# CKGEN_CM_CORE register map
Vendor: Texas Instruments
Peripheral module from a debugger description file (folder omap5430_ES2_PUBLIC).
Registers are 32-bit, access per field, reset 0x0 unless marked. A register's access mark holds for its fields unless they carry their own. Offsets are as the file gives them; lines under a group give offsets from that group; [hi:lo] are bit positions; {n}, {i} and the like mark numbered series; 'fields as' and 'values as' point back to an identical list; <NAME> marks a mode.

## CKGEN_CM_CORE
0x04 CM_CLKSEL_USB_60MHZ reset 0x1 — Selects the configuration of the divider generating 60MHz clock for USB from the DPLL_USB o/p.
  [0] CLKSEL rw — Select the configuration of the divider
    0=SEL_DIV_1 (Set the divider in bypass mode to support bypass clock from DPLL_USB to pass through without division.); 1=SEL_DIV_8 (Set the divider to divide the DPLL o/p (480MHz typical) by 8 to generate 60MHz clock, to be used for both OPP_NOM and OPP_LOW.)
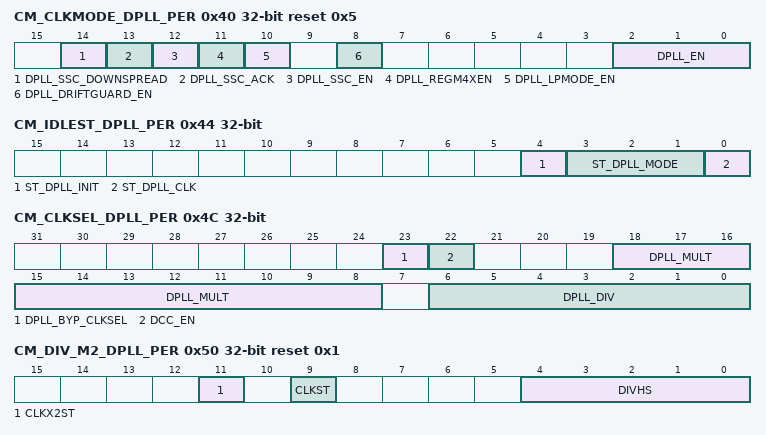
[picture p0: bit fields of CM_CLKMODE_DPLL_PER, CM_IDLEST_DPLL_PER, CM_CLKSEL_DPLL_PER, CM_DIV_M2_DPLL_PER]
0x40 CM_CLKMODE_DPLL_PER reset 0x5 — This register allows controlling the DPLL modes.
  [14] DPLL_SSC_DOWNSPREAD rw — Control if only low frequency spread is required
    0=FULL_SPREAD (When SSC is enabled, clock frequency is spread on both sides of the programmed frequency); 1=LOW_SPREAD (When SSC is enabled, clock frequency is spread only on the lower side of the programmed frequency)
  [13] DPLL_SSC_ACK ro — Acknowledgement from the DPLL regarding start and stop of Spread Spectrum Clocking feature
    0=Disabled (SSC has been turned off on PLL o/ps); 1=Enabled (SSC has been turned on on PLL o/ps)
  [12] DPLL_SSC_EN rw — Enable or disable Spread Spectrum Clocking
    0=Disabled (SSC disabled); 1=Enabled (SSC enabled)
  [11] DPLL_REGM4XEN ro — Enable the REGM4XEN mode of the DPLL.
    0=DISABLED (REGM4XEN mode of the DPLL is disabled)
  [10] DPLL_LPMODE_EN rw — Set the DPLL in Low Power mode. Check the DPLL documentation to see when this can be enabled.
    0=DISABLED (Low power mode of the DPLL is disabled); 1=ENABLED (Low power mode of the DPLL is enabled)
  [8] DPLL_DRIFTGUARD_EN rw — This bit allows to enable or disable the automatic recalibration feature of the DPLL. The DPLL will automatically start a recalibration process upon assertion of the DPLL's RECAL flag if this bit is set.
    0=Diasbled (DRIFTGUARD feature is disabled); 1=Enabled (DRIFTGUARD feature is enabled)
  [2:0] DPLL_EN rw — DPLL control
    5=DPLL_LP_BYP_MODE (Put the DPLL in Idle Bypass Low Power mode.); 6=DPLL_FR_BYP_MODE (Put the DPLL in Idle Bypass Fast Relock mode.); 7=DPLL_LOCK_MODE (Enables the DPLL in Lock mode)
0x44 CM_IDLEST_DPLL_PER ro — This register allows monitoring DPLL activity. This register is read only and automatically updated. [warm reset insensitive]
  [4] ST_DPLL_INIT — DPLL init status (for debug purpose).
    1=DPLL_INIT (DPLL has been init); 0=DPLL_NOTINIT (DPLL is not init)
  [3:1] ST_DPLL_MODE — DPLL mode status (for debug purpose)
    0=Transient state. From reset to any LP (low power) idle state or from any power state to any power state (Power states are Low Power Stop mode, Fast Relock Stop mode, Idle Bypass Low Power mode and Idle Bypass Fast Relock mode).; 1=LP_STOP (The DPLL is in Low Power Stop mode); 2=FR_STOP (The DPLL is in Fast Relock Stop mode); 5=LP_BYP (The DPLL is in Idle Bypass Low Power mode); 6=FR_BYP (The DPLL is in Idle Bypass Fast Relock mode)
  [0] ST_DPLL_CLK — DPLL lock status
    1=DPLL_LOCKED (DPLL is LOCKED); 0=DPLL_UNLOCKED (DPLL is either in bypass mode or in stop mode.)
0x48 CM_AUTOIDLE_DPLL_PER — This register provides automatic control over the DPLL activity.
  [2:0] AUTO_DPLL_MODE rw — DPLL automatic control;
    0=AUTO_CTL_DISABLE (DPLL auto control disabled); 1=AUTO_LP_STOP (The DPLL is automatically put in Low Power Stop mode when its DPLL generated clocks are not required anymore. It is also restarted automatically.); 2=AUTO_FR_STOP (The DPLL is automatically put in Fast Relock Stop mode when its DPLL generated clocks are not required anymore. It is also restarted automatically.); 5=AUTO_LP_BYP (The DPLL is automatically put in Idle Bypass Low Power mode when its DPLL generated clocks are not required anymore. It is also restarted automatically.); 6=AUTO_FR_BYP (The DPLL is automatically put in Idle Bypass Fast Relock mode when its DPLL generated clocks are not required anymore. It is also restarted automatically.)
0x4C CM_CLKSEL_DPLL_PER — This register provides controls over the DPLL.
  [23] DPLL_BYP_CLKSEL rw — Allows control of the BYPASS clock of the PLL and the associated HSDIVIDER. Same as ULOWCLKEN on DPLL. In DPLL Locked mode, 0 - No impact 1 - No impact In DPLL Bypass mode, 0 - CLKINP is selected as the BYPASS clock for CLKOUT/CLKOUTX2, 1 - CLKINPULOW is selected as the BYPASS clock for CLKOUT/CLKOUTX2
  [22] DCC_EN ro — Duty-cycle corrector for high frequency clock Read 0: Duty-cycle corrector is disabled
  [18:8] DPLL_MULT rw — DPLL multiplier factor (2 to 2047). Equal to input M of DPLL; M=2 to 2047 = DPLL multiplies by M. [warm reset insensitive]
  [6:0] DPLL_DIV rw — DPLL divider factor (0 to 127) Equal to input N of DPLL; actual division factor is N+1. [warm reset insensitive]
0x50 CM_DIV_M2_DPLL_PER reset 0x1 — This register provides controls over the M2 divider of the DPLL.
  [11] CLKX2ST ro — DPLL CLKOUTX2 status
    0=CLK_GATED (The clock output is gated); 1=CLK_ENABLED (The clock output is enabled)
  [9] CLKST ro — DPLL CLKOUT status
    values as CLKX2ST
  [4:0] DIVHS rw — DPLL M2 post-divider factor (1 to 31).
    4=Reserved (4, to be used for both OPP_NOM and OPP_LOW)
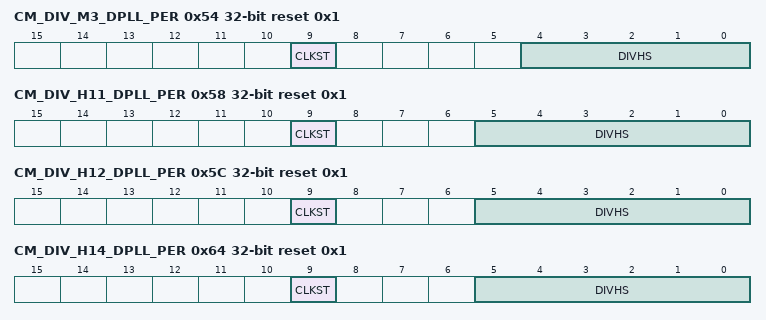
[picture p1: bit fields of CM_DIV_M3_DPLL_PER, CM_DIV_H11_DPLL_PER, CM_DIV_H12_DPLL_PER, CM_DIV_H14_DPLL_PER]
0x54 CM_DIV_M3_DPLL_PER reset 0x1 — This register provides controls over the M3 divider of the DPLL.
  [9] CLKST ro — DPLL CLKOUTHIF status
    values as CM_DIV_M2_DPLL_PER.CLKX2ST
  [4:0] DIVHS rw — DPLL M3 post-divider factor (1 to 31). The values listed for 0x3 and 0x4 are used for maximum supported frequency at each OPP. Higher dividers (max 31), thus lower frequencies, are also supported.
    3=OPP_NOM_DPLL_PER_3 (3, to be used for OPP_NOM (when DPLL_PER is locked at 768MHz)); 4=Reserved (4, to be used for OPP_LOW (when DPLL_PER is locked at 768MHz))
0x58 CM_DIV_H11_DPLL_PER reset 0x1 — This register provides controls over the CLKOUT1 o/p of the HSDIVIDER1.
  [9] CLKST ro — HSDIVIDER1 CLKOUT1 status
    values as CM_DIV_M2_DPLL_PER.CLKX2ST
  [5:0] DIVHS rw — DPLL (H11+1) post-divider factor (1 to 63).
    6=Reserved (6, to be used for both OPP_NOM and OPP_LOW (when DPLL_PER is locked at 768MHz))
0x5C CM_DIV_H12_DPLL_PER reset 0x1 — This register provides controls over the CLKOUT2 o/p of the HSDIVIDER1.
  [9] CLKST ro — HSDIVIDER1 CLKOUT2 status
    values as CM_DIV_M2_DPLL_PER.CLKX2ST
  [5:0] DIVHS rw — DPLL (H12+1) post-divider factor (1 to 63).
    4=Reserved (4, to be used for both OPP_NOM and OPP_LOW)
0x64 CM_DIV_H14_DPLL_PER reset 0x1 — This register provides controls over the CLKOUT4 o/p of the HSDIVIDER1.
  [9] CLKST ro — HSDIVIDER1 CLKOUT4 status
    values as CM_DIV_M2_DPLL_PER.CLKX2ST
  [5:0] DIVHS rw — DPLL (H14+1) post-divider factor (1 to 63).
    2=2,_to_be_used_for_OPP_NOM; 4=Reserved (4, to be used for OPP_LOW)
0x68 CM_SSC_DELTAMSTEP_DPLL_PER — Control the DeltaMStep parameter for Spread Spectrum Clocking. [warm reset insensitive]
  [19:0] DELTAMSTEP rw — DeltaMStep is split into fractional and integer part. For Triangular Spread Spectrum: [19:18] for integer part, [17:0] for fractional part For Square Wave Spread Spectrum [19:14] for integer part, [13:0] for fractional part
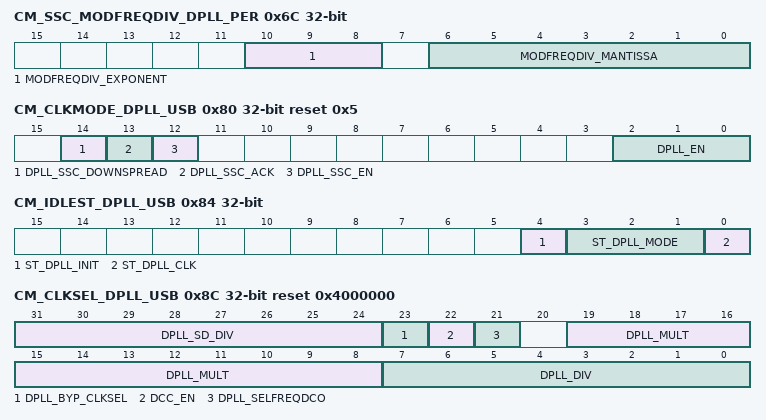
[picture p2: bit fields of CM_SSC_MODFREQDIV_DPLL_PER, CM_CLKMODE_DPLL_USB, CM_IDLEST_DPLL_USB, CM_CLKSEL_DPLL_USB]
0x6C CM_SSC_MODFREQDIV_DPLL_PER — Control the Modulation Frequency (Fm) for Spread Spectrum. [warm reset insensitive]
  [10:8] MODFREQDIV_EXPONENT rw — Set the Exponent component of MODFREQDIV factor
  [6:0] MODFREQDIV_MANTISSA rw — Set the Mantissa component of MODFREQDIV factor
0x80 CM_CLKMODE_DPLL_USB reset 0x5 — This register allows controlling the DPLL_USB modes.
  [14] DPLL_SSC_DOWNSPREAD rw — Control if only low frequency spread is required
    values as CM_CLKMODE_DPLL_PER.DPLL_SSC_DOWNSPREAD
  [13] DPLL_SSC_ACK ro — Acknowledgement from the DPLL regarding start and stop of Spread Spectrum Clocking feature
    values as CM_CLKMODE_DPLL_PER.DPLL_SSC_ACK
  [12] DPLL_SSC_EN rw — Enable or disable Spread Spectrum Clocking
    0=Disabled (SSC disabled); 1=Enabled (SSC enabled)
  [2:0] DPLL_EN rw — DPLL control. Upon Warm Reset, the PRCM DPLL control state machine updates this register to reflect DPLL Low Power Stop mode.
    1=DPLL_LP_STP_MODE (Put the DPLL in Low Power Stop mode); 5=DPLL_LP_BYP_MODE (Put the DPLL in Idle Bypass Low Power mode.); 7=DPLL_LOCK_MODE (Enables the DPLL in Lock mode)
0x84 CM_IDLEST_DPLL_USB ro — This register allows monitoring DPLL activity. This register is read only and automatically updated. [warm reset insensitive]
  [4] ST_DPLL_INIT — DPLL init status (for debug purpose).
    values as CM_IDLEST_DPLL_PER.ST_DPLL_INIT
  [3:1] ST_DPLL_MODE — DPLL mode status (for debug purpose).
    0=Transient state. From reset to any LP (low power) idle state or from any power state to any power state (Power states are Low Power Stop mode, Fast Relock Stop mode, Idle Bypass Low Power mode and Idle Bypass Fast Relock mode).; 1=LP_STOP (The DPLL is in Low Power Stop mode); 5=LP_BYP (The DPLL is in Idle Bypass Low Power mode)
  [0] ST_DPLL_CLK — DPLL lock status
    values as CM_IDLEST_DPLL_PER.ST_DPLL_CLK
0x88 CM_AUTOIDLE_DPLL_USB — This register provides automatic control over the DPLL activity.
  [2:0] AUTO_DPLL_MODE rw — DPLL automatic control;
    0=AUTO_CTL_DISABLE (DPLL auto control disabled); 1=AUTO_LP_STOP (The DPLL is automatically put in Low Power Stop mode when its DPLL generated clocks are not required anymore. It is also restarted automatically.); 5=AUTO_LP_BYP (The DPLL is automatically put in Idle Bypass Low Power mode when its DPLL generated clocks are not required anymore. It is also restarted automatically.)
0x8C CM_CLKSEL_DPLL_USB reset 0x4000000 — This register provides controls over the DPLL.
  [31:24] DPLL_SD_DIV rw — Sigma-Delta divider select (2-255). This factor must be set by software to ensure optimum jitter performance. DPLL_SD_DIV = CEILING ([DPLL_MULT/(DPLL_DIV+1)] * CLKINP / 250), where CLKINP is the input clock of the DPLL in MHz). DPLL_MULT must be set with M multiplier factor and DPLL_DIV with N divider factor, and must not be changed once DPLL is locked. For more information, see , .
  [23] DPLL_BYP_CLKSEL rw — Allows control of the BYPASS clock of the PLL and the associated HSDIVIDER. Same as ULOWCLKEN on DPLL. In DPLL Locked mode, 0 - No impact 1 - No impact In DPLL Bypass mode, 0 - CLKINP is selected as the BYPASS clock for CLKOUT 1 - CLKINPULOW is selected as the BYPASS clock for CLKOUT
  [22] DCC_EN ro — Duty-cycle corrector for high frequency clock Read 0: Duty-cycle corrector is disabled
  [21] DPLL_SELFREQDCO rw — Select DCO output according to required frequency. 0x0: DCO clock is 1500MHz SELFREQDCO input of DPLL is set to '010' 0x1: DCO clock is 1250MHz SELFREQDCO input of DPLL is set to '100''
  [19:8] DPLL_MULT rw — DPLL multiplier factor (2 to 4095). Equal to input M (multiplier) factor of DPLL; M=2 to 4095 = DPLL multiplies by M. [warm reset insensitive]
  [7:0] DPLL_DIV rw — DPLL divider factor (0 to 255) Equal to input N (divider) factor of DPLL; actual division factor is N+1 [warm reset insensitive]
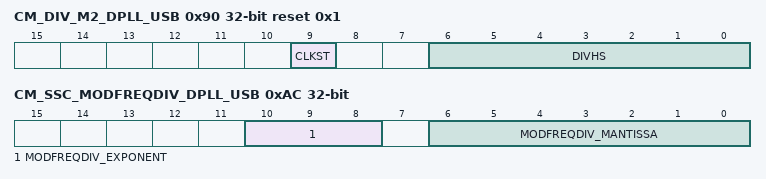
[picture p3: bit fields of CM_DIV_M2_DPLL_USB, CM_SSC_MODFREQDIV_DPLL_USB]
0x90 CM_DIV_M2_DPLL_USB reset 0x1 — This register provides controls over the M2 divider of the DPLL.
  [9] CLKST ro — DPLL CLKOUT status
    values as CM_DIV_M2_DPLL_PER.CLKX2ST
  [6:0] DIVHS rw — DPLL M2 post-divider factor (1 to 127).
    2=Reserved (2, to be used for both OPP_NOM and OPP_LOW)
0xA8 CM_SSC_DELTAMSTEP_DPLL_USB — Control the DeltaMStep parameter for Spread Spectrum Clocking. [warm reset insensitive]
  [20:0] DELTAMSTEP rw — DeltaMStep is split into fractional and integer part. For Triangular Spread Spectrum: [20:18] for integer part, [17:0] for fractional part For Square Wave Spread Spectrum [19:14] for integer part, [13:0] for fractional part
0xAC CM_SSC_MODFREQDIV_DPLL_USB — Control the Modulation Frequency (Fm) for Spread Spectrum. [warm reset insensitive]
  fields as CM_SSC_MODFREQDIV_DPLL_PER
0xB4 CM_CLKDCOLDO_DPLL_USB ro — This register provides status over CLKDCOLDO output of the DPLL.
  [9] ST_DPLL_CLKDCOLDO — DPLL CLKDCOLDO status
    values as CM_DIV_M2_DPLL_PER.CLKX2ST
